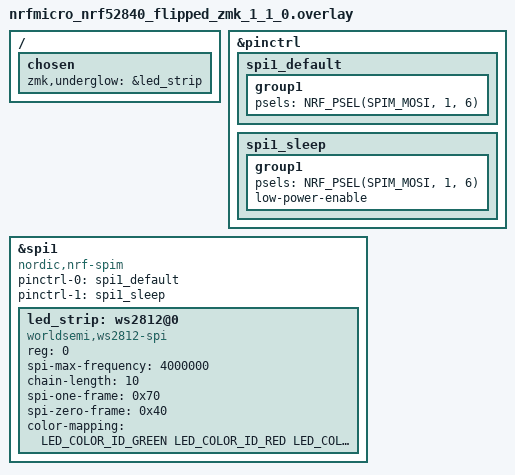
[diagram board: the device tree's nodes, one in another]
#include <dt-bindings/led/led.h>

&pinctrl {
    spi1_default: spi1_default {
        group1 {
            psels = <NRF_PSEL(SPIM_MOSI, 1, 6)>;
        };
    };

    spi1_sleep: spi1_sleep {
        group1 {
            psels = <NRF_PSEL(SPIM_MOSI, 1, 6)>;
            low-power-enable;
        };
    };
};

&spi1 {
    compatible = "nordic,nrf-spim";
    status = "okay";

    pinctrl-0 = <&spi1_default>;
    pinctrl-1 = <&spi1_sleep>;
    pinctrl-names = "default", "sleep";

    led_strip: ws2812@0 {
        compatible = "worldsemi,ws2812-spi";

        /* SPI */
        reg = <0>; /* ignored, but necessary for SPI bindings */
        spi-max-frequency = <4000000>;

        /* WS2812 */
        chain-length = <10>; /* arbitrary; change at will */
        spi-one-frame = <0x70>;
        spi-zero-frame = <0x40>;

        color-mapping = <LED_COLOR_ID_GREEN LED_COLOR_ID_RED LED_COLOR_ID_BLUE>;
    };
};

/ {
    chosen {
        zmk,underglow = &led_strip;
    };
};
